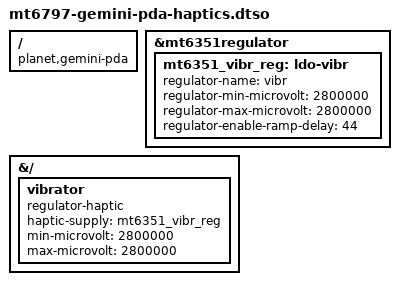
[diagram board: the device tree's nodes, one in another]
// SPDX-License-Identifier: (GPL-2.0-only OR MIT)
/*
 * Planet Computers Gemini PDA vibration motor.
 *
 * The motor runs directly from the MT6351 VIBR LDO: the vendor device tree
 * has a "mediatek,vibrator" node with vib_vol = 5, the index of 2.8 V in the
 * VIBR voltage table, and no other control. Describe the LDO at that one
 * voltage and drive it with the generic regulator haptic driver.
 */

/dts-v1/;
/plugin/;

/ {
	compatible = "planet,gemini-pda", "mediatek,mt6797";
};

&mt6351regulator {
	mt6351_vibr_reg: ldo-vibr {
		regulator-name = "vibr";
		regulator-min-microvolt = <2800000>;
		regulator-max-microvolt = <2800000>;
		regulator-enable-ramp-delay = <44>;
	};
};

&{/} {
	vibrator {
		compatible = "regulator-haptic";
		haptic-supply = <&mt6351_vibr_reg>;
		min-microvolt = <2800000>;
		max-microvolt = <2800000>;
	};
};
